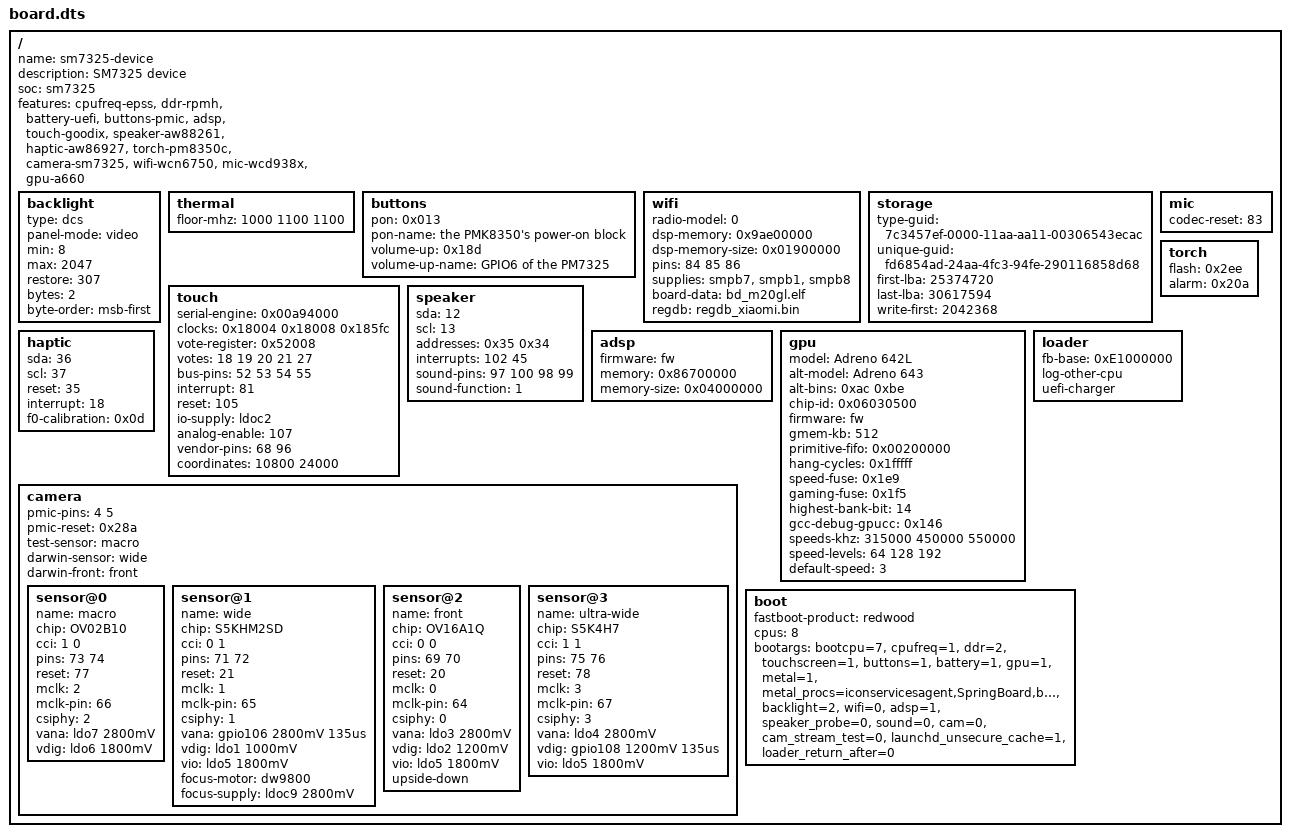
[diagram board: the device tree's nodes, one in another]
/dts-v1/;

// SM7325 device. Sources: the phone's Android device tree (Xiaomi's SM7325 display tree, the panel
// dsi_m20_36_02_0a_dsc_vid) and what was measured on the phone under Darwin 16.5 (base/README.md).
/ {
	name = "sm7325-device";                       // what the loader puts in /chosen/darwin-board
	description = "SM7325 device";
	soc = "sm7325";

	features = "cpufreq-epss", "ddr-rpmh", "battery-uefi", "buttons-pmic", "adsp", "touch-goodix", "speaker-aw88261", "haptic-aw86927", "torch-pm8350c", "camera-sm7325", "wifi-wcn6750", "mic-wcd938x", "gpu-a660";

	// A video-mode AMOLED panel whose brightness is MIPI DCS 0x51.
	backlight {
		type = "dcs";
		panel-mode = "video";
		min = <8>;                      // qcom,mdss-dsi-bl-min-level
		max = <2047>;                   // of qcom,mdss-dsi-bl-max-level 4095: 2047 and up is its high brightness mode
		restore = <307>;                // qcom,mdss-brightness-init-level
		bytes = <2>;
		byte-order = "msb-first";       // qcom,mdss-dsi-bl-inverted-dbv
	};

	thermal {
		floor-mhz = <1000 1100 1100>;
	};

	// The keys on the PMICs: a peripheral is SPMI slave << 8 | the high byte of its registers.
	buttons {
		pon = <0x013>;                  // pon_hlos@1300 of the PMK8350 (slave 0): power, and volume down on RESIN_N
		pon-name = "the PMK8350's power-on block";
		volume-up = <0x18d>;            // gpio_keys: GPIO6 of the PM7325 (slave 1)
		volume-up-name = "GPIO6 of the PM7325";
	};

	// The audio DSP, and the battery manager behind it.
	// The Wi-Fi radio: a WCN6750 on the SoC's own Wi-Fi DSP, whose image goes into that DSP's reserved
	// memory (wlan@9ae00000 in the SoC's tree).
	wifi {
		radio-model = <0>;
		dsp-memory = <0x9ae00000>;
		dsp-memory-size = <0x01900000>;
		pins = <84 85 86>;              // the radio's enable, Bluetooth's reset, Bluetooth's sw-ctrl
		supplies = "smpb7", "smpb1", "smpb8"; // PM7325 S7, S1, S8: vdd-cx-mx, vdd-1.8-xo, vdd-1.3-rfa
		board-data = "bd_m20gl.elf";            // what the phone's Android sends the radio
		regdb = "regdb_xiaomi.bin";
	};

	// The port's own partition on the phone's storage, "darwin": 20 GiB at the end of logical unit 0. It is the
	// one partition the kernel may write (ufs_write=1), and only from the block past what the build puts there
	// (the Darwin volume and the two cryptexes). Its GPT entry, as the partition table of this phone has it.
	storage {
		type-guid = "7c3457ef-0000-11aa-aa11-00306543ecac";
		unique-guid = "fd6854ad-24aa-4fc3-94fe-290116858d68";
		first-lba = <25374720>;
		last-lba = <30617594>;
		write-first = <2042368>;
	};

	// The touch controller (Goodix, or FocalTech on some units: two straps say which): on serial engine 13
	// (qupv3_se13_spi, spi@a94000), GPIO 52 to 55; its interrupt on GPIO 81, its reset on GPIO 105; its I/O
	// supply is L2C (1.8 V), its analog supply is switched on by GPIO 107. The clocks and their votes are
	// gcc-yupik.c's for that engine: wrapper 1's two bus clocks and its sixth engine.
	touch {
		serial-engine = <0x00a94000>;
		clocks = <0x18004 0x18008 0x185fc>;
		vote-register = <0x52008>;
		votes = <18 19 20 21 27>;
		bus-pins = <52 53 54 55>;
		interrupt = <81>;
		reset = <105>;
		io-supply = "ldoc2";
		analog-enable = <107>;
		vendor-pins = <68 96>;
		coordinates = <10800 24000>;            // goodix,panel-max-x and -y
	};

	// The speaker's two amplifiers, AW88261: their I2C bus on GPIO 12 (data) and 13 (clock); the one at 0x35
	// plays the sound's slot 0 and has its interrupt on GPIO 102, the one at 0x34 slot 1 and GPIO 45.
	speaker {
		sda = <12>;
		scl = <13>;
		addresses = <0x35 0x34>;
		interrupts = <102 45>;
		sound-pins = <97 100 98 99>;
		sound-function = <1>;
	};

	// The microphones' codec (a WCD938x on the SoC's SoundWire): the one pin of the SoC it has, its reset.
	mic {
		codec-reset = <83>;
	};

	// The vibration motor's chip, an AW86927: its I2C bus on GPIO 36 (data) and 37 (clock), reset on GPIO 35,
	// interrupt on GPIO 18; f0-calibration is what Android's driver found for this motor ("f0_cali_data = 0x0D").
	haptic {
		sda = <36>;
		scl = <37>;
		reset = <35>;
		interrupt = <18>;
		f0-calibration = <0x0d>;
	};

	// The flashlight: the flash LED module and the temperature alarm of the PM8350C, which is slave 2 on the
	// PMICs' bus (qcom,pm8350c@2: qcom,flash_led@ee00, qcom,temp-alarm@a00).
	torch {
		flash = <0x2ee>;
		alarm = <0x20a>;
	};

	adsp {
		firmware = "fw";
		memory = <0x86700000>;          // the DSP's reserved memory (adsp@86700000)
		memory-size = <0x04000000>;     // 64 MiB of it
	};

	// The GPU. Sources: yupik-gpu.dtsi, Linux's adreno-gpulist.h and adreno_a6xx_gmu.c.
	gpu {
		model = "Adreno 642L";
		alt-model = "Adreno 643";       // qcom,gpu-models: what the parts with these speed bins are sold as
		alt-bins = <0xac 0xbe>;
		chip-id = <0x06030500>;
		firmware = "fw";
		gmem-kb = <512>;
		primitive-fifo = <0x00200000>;
		hang-cycles = <0x1fffff>;
		speed-fuse = <0x1e9>;
		gaming-fuse = <0x1f5>;
		highest-bank-bit = <14>;        // LPDDR4X (a6xx_init)
		gcc-debug-gpucc = <0x146>;
		// (not zap-must-authenticate: this phone's firmware leaves a zap shader loaded, which is used when ours is refused)
		speeds-khz = <315000 450000 550000>;
		speed-levels = <64 128 192>;
		default-speed = <3>;
	};

	// The cameras (feature "camera-sm7325"). The PM8008 whose regulators feed the sensors is on the I2C bus of
	// GPIO 4 and 5. Each sensor as Android's device tree has it (cam-sensor2, 0, 1 and 3, in this order, which
	// is the one Darwin's side numbers them in): its CCI master and that master's pins, its reset, which MCLK and
	// that clock's pin, the CSI receiver, and how the module file's power sequence switches its supplies.
	camera {
		pmic-pins = <4 5>;
		pmic-reset = <0x28a>;           // the PM8350C's (SPMI slave 2) GPIO 3
		test-sensor = "macro";
		darwin-sensor = "wide";
		darwin-front = "front";

		sensor@0 {
			name = "macro";
			chip = "OV02B10";
			cci = <1 0>;
			pins = <73 74>;
			reset = <77>;
			mclk = <2>;
			mclk-pin = <66>;
			csiphy = <2>;
			vana = "ldo7 2800mV";
			vdig = "ldo6 1800mV";
		};

		sensor@1 {
			name = "wide";
			chip = "S5KHM2SD";
			cci = <0 1>;
			pins = <71 72>;
			reset = <21>;
			mclk = <1>;
			mclk-pin = <65>;
			csiphy = <1>;
			vana = "gpio106 2800mV 135us"; // camera_wide_vana_ldo: a fixed regulator from BOB
			vdig = "ldo1 1000mV";
			vio = "ldo5 1800mV";
			focus-motor = "dw9800";
			focus-supply = "ldoc9 2800mV";  // cam_vaf: the PM8350C's L9
		};

		sensor@2 {
			name = "front";
			chip = "OV16A1Q";
			cci = <0 0>;
			pins = <69 70>;
			reset = <20>;
			mclk = <0>;
			mclk-pin = <64>;
			csiphy = <0>;
			vana = "ldo3 2800mV";
			vdig = "ldo2 1200mV";
			vio = "ldo5 1800mV";
			upside-down;
		};

		sensor@3 {
			name = "ultra-wide";
			chip = "S5K4H7";
			cci = <1 1>;
			pins = <75 76>;
			reset = <78>;
			mclk = <3>;
			mclk-pin = <67>;
			csiphy = <3>;
			vana = "ldo4 2800mV";
			vdig = "gpio108 1200mV 135us"; // camera_ultra_dvdd_ldo: a fixed regulator from the PM7325's S8
			vio = "ldo5 1800mV";
		};
	};

	// The loader (loader/) under this phone's UEFI. It tells boards apart by the framebuffer the UEFI reports.
	loader {
		fb-base = <0xE1000000>;         // the loader prints it at start: "display W x H at ..."
		log-other-cpu;
		uefi-charger;                   // the UEFI's Qualcomm charger protocols give the battery's state
	};

	// Darwin 27's default RAM boot profile for the SM7325 device.
	boot {
		fastboot-product = "redwood";
		cpus = <8>;                     // expose all four Cortex-A78 and four Cortex-A55 cores
		bootargs = "bootcpu=7", "cpufreq=1", "ddr=2", "touchscreen=1", "buttons=1", "battery=1",
		           "gpu=1", "metal=1", "metal_procs=iconservicesagent,SpringBoard,backboardd", "backlight=2",
		           "wifi=0", "adsp=1", "speaker_probe=0", "sound=0", "cam=0",
		           "cam_stream_test=0", "launchd_unsecure_cache=1", "loader_return_after=0";
	};
};
